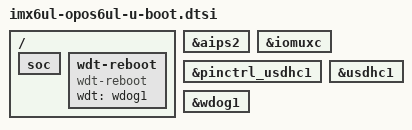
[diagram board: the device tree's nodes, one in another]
// SPDX-License-Identifier: GPL-2.0
/*
 * Device Tree Source extras for U-Boot for the OPOS6UL SoM
 *
 * Copyright (C) 2018 Armadeus Systems <support@armadeus.com>
 */

/ {
	soc {
		bootph-pre-ram;
	};

	wdt-reboot {
		compatible = "wdt-reboot";
		wdt = <&wdog1>;
		bootph-pre-ram;
	};
};

&aips2 {
	bootph-pre-ram;
};

&iomuxc {
	bootph-pre-ram;
};

&pinctrl_usdhc1 {
	bootph-pre-ram;
};

&usdhc1 {
	bootph-pre-ram;
};

&wdog1 {
	bootph-pre-ram;
};
